VERSION ""

NS_ :

BS_:

BU_:

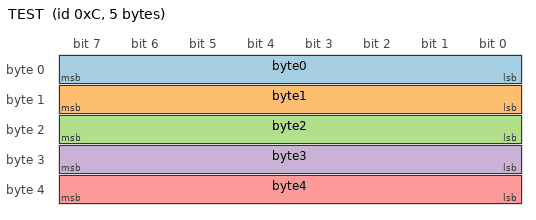
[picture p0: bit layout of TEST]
BO_ 12 TEST: 5 Vector__XXX
 SG_ byte0 : 0|8@1+ (1,0) [0|0] "" Vector__XXX
 SG_ byte1 : 8|8@1+ (1,0) [0|0] "" Vector__XXX
 SG_ byte2 : 16|8@1+ (1,0) [0|0] "" Vector__XXX
 SG_ byte3 : 24|8@1+ (1,0) [0|0] "" Vector__XXX
 SG_ byte4 : 32|8@1+ (1,0) [0|0] "" Vector__XXX

BA_DEF_  "BusType" STRING ;
BA_DEF_DEF_  "BusType" "CAN";
